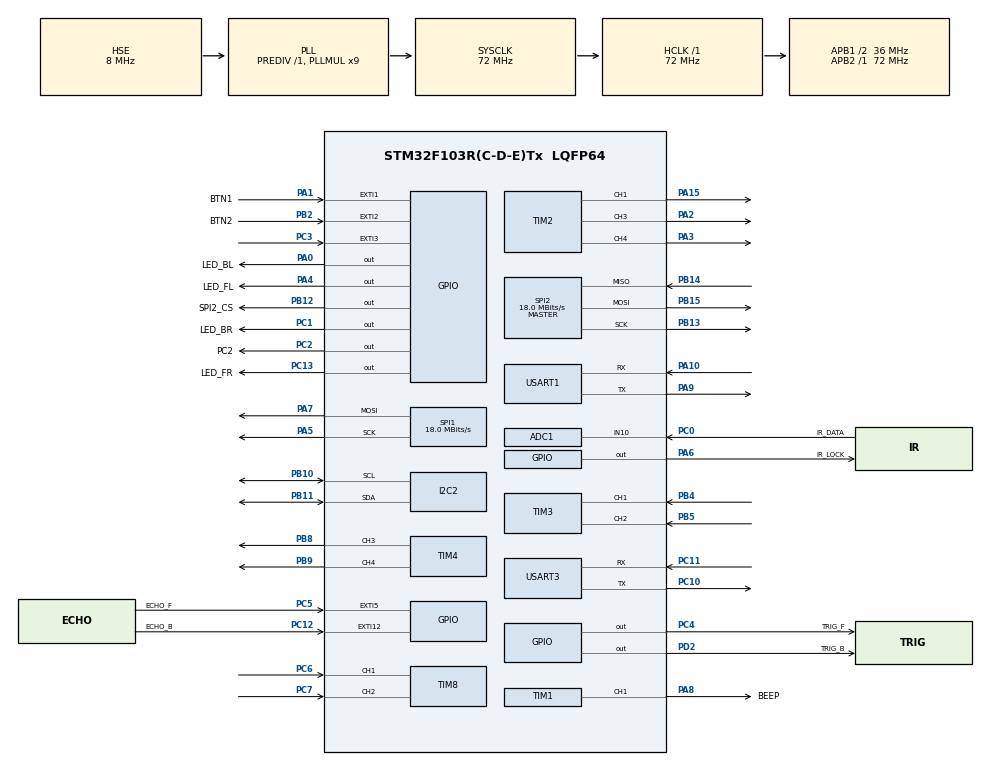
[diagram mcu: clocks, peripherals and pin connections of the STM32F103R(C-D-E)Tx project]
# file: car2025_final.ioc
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ADC1.Channel-9\#ChannelRegularConversion=ADC_CHANNEL_10
ADC1.NbrOfConversionFlag=1
ADC1.Rank-9\#ChannelRegularConversion=1
ADC1.SamplingTime-9\#ChannelRegularConversion=ADC_SAMPLETIME_13CYCLES_5
ADC1.master=1
Dma.ADC1.4.Direction=DMA_PERIPH_TO_MEMORY
Dma.ADC1.4.Instance=DMA1_Channel1
Dma.ADC1.4.MemDataAlignment=DMA_MDATAALIGN_HALFWORD
Dma.ADC1.4.MemInc=DMA_MINC_ENABLE
Dma.ADC1.4.Mode=DMA_NORMAL
Dma.ADC1.4.PeriphDataAlignment=DMA_PDATAALIGN_HALFWORD
Dma.ADC1.4.PeriphInc=DMA_PINC_DISABLE
Dma.ADC1.4.Priority=DMA_PRIORITY_LOW
Dma.Request0=USART1_RX
Dma.Request1=USART1_TX
Dma.Request2=USART3_RX
Dma.Request3=USART3_TX
Dma.Request4=ADC1
Dma.USART1_RX.0.Direction=DMA_PERIPH_TO_MEMORY
Dma.USART1_RX.0.Instance=DMA1_Channel5
Dma.USART1_RX.0.MemDataAlignment=DMA_MDATAALIGN_BYTE
Dma.USART1_RX.0.MemInc=DMA_MINC_ENABLE
Dma.USART1_RX.0.Mode=DMA_NORMAL
Dma.USART1_RX.0.PeriphDataAlignment=DMA_PDATAALIGN_BYTE
Dma.USART1_RX.0.PeriphInc=DMA_PINC_DISABLE
Dma.USART1_RX.0.Priority=DMA_PRIORITY_LOW
Dma.USART1_TX.1.Direction=DMA_MEMORY_TO_PERIPH
Dma.USART1_TX.1.Instance=DMA1_Channel4
Dma.USART1_TX.1.MemDataAlignment=DMA_MDATAALIGN_BYTE
Dma.USART1_TX.1.MemInc=DMA_MINC_ENABLE
Dma.USART1_TX.1.Mode=DMA_NORMAL
Dma.USART1_TX.1.PeriphDataAlignment=DMA_PDATAALIGN_BYTE
Dma.USART1_TX.1.PeriphInc=DMA_PINC_DISABLE
Dma.USART1_TX.1.Priority=DMA_PRIORITY_LOW
Dma.USART3_RX.2.Direction=DMA_PERIPH_TO_MEMORY
Dma.USART3_RX.2.Instance=DMA1_Channel3
Dma.USART3_RX.2.MemDataAlignment=DMA_MDATAALIGN_BYTE
Dma.USART3_RX.2.MemInc=DMA_MINC_ENABLE
Dma.USART3_RX.2.Mode=DMA_NORMAL
Dma.USART3_RX.2.PeriphDataAlignment=DMA_PDATAALIGN_BYTE
Dma.USART3_RX.2.PeriphInc=DMA_PINC_DISABLE
Dma.USART3_RX.2.Priority=DMA_PRIORITY_LOW
Dma.USART3_TX.3.Direction=DMA_MEMORY_TO_PERIPH
Dma.USART3_TX.3.Instance=DMA1_Channel2
Dma.USART3_TX.3.MemDataAlignment=DMA_MDATAALIGN_BYTE
Dma.USART3_TX.3.MemInc=DMA_MINC_ENABLE
Dma.USART3_TX.3.Mode=DMA_NORMAL
Dma.USART3_TX.3.PeriphDataAlignment=DMA_PDATAALIGN_BYTE
Dma.USART3_TX.3.PeriphInc=DMA_PINC_DISABLE
Dma.USART3_TX.3.Priority=DMA_PRIORITY_LOW
I2C2.I2C_Mode=I2C_Standard
Mcu.Family=STM32F1
Mcu.Name=STM32F103R(C-D-E)Tx
Mcu.Package=LQFP64
NVIC.ADC1_2_IRQn=true\:0\:0\:false\:false\:true\:true\:true\:true
NVIC.DMA1_Channel1_IRQn=true\:0\:0\:false\:false\:true\:false\:true\:true
NVIC.DMA1_Channel2_IRQn=true\:0\:0\:false\:false\:true\:false\:true\:true
NVIC.DMA1_Channel3_IRQn=true\:0\:0\:false\:false\:true\:false\:true\:true
NVIC.DMA1_Channel4_IRQn=true\:0\:0\:false\:false\:true\:false\:true\:true
NVIC.DMA1_Channel5_IRQn=true\:0\:0\:false\:false\:true\:false\:true\:true
NVIC.EXTI15_10_IRQn=true\:6\:0\:true\:false\:true\:true\:true\:true
NVIC.EXTI1_IRQn=true\:8\:0\:true\:false\:true\:true\:true\:true
NVIC.EXTI2_IRQn=true\:8\:0\:true\:false\:true\:true\:true\:true
NVIC.EXTI3_IRQn=true\:8\:0\:true\:false\:true\:true\:true\:true
NVIC.EXTI9_5_IRQn=true\:6\:0\:true\:false\:true\:true\:true\:true
NVIC.PriorityGroup=NVIC_PRIORITYGROUP_4
NVIC.TIM5_IRQn=true\:8\:0\:true\:false\:true\:true\:true\:true
NVIC.TIM6_IRQn=true\:5\:0\:true\:false\:true\:true\:true\:true
NVIC.TIM7_IRQn=true\:13\:0\:true\:false\:true\:true\:true\:true
NVIC.USART1_IRQn=true\:14\:0\:true\:false\:true\:true\:true\:true
NVIC.USART3_IRQn=true\:14\:0\:true\:false\:true\:true\:true\:true
PA0-WKUP.GPIO_Label=LED_BL
PA0-WKUP.Signal=GPIO_Output
PA1.GPIO_Label=BTN1
PA1.Signal=GPXTI1
PA10.Mode=Asynchronous
PA10.Signal=USART1_RX
PA13.Mode=Serial_Wire
PA13.Signal=SYS_JTMS-SWDIO
PA14.Mode=Serial_Wire
PA14.Signal=SYS_JTCK-SWCLK
PA15.Signal=S_TIM2_CH1_ETR
PA2.Signal=S_TIM2_CH3
PA3.Signal=S_TIM2_CH4
PA4.GPIO_Label=LED_FL
PA4.Signal=GPIO_Output
PA5.Mode=TX_Only_Simplex_Unidirect_Master
PA5.Signal=SPI1_SCK
PA6.GPIO_Label=IR_LOCK
PA6.Signal=GPIO_Output
PA7.Mode=TX_Only_Simplex_Unidirect_Master
PA7.Signal=SPI1_MOSI
PA8.GPIO_Label=BEEP
PA8.Signal=S_TIM1_CH1
PA9.Mode=Asynchronous
PA9.Signal=USART1_TX
PB10.Mode=I2C
PB10.Signal=I2C2_SCL
PB11.Mode=I2C
PB11.Signal=I2C2_SDA
PB12.GPIO_Label=SPI2_CS
PB12.GPIO_Speed=GPIO_SPEED_FREQ_HIGH
PB12.Signal=GPIO_Output
PB13.Mode=Full_Duplex_Master
PB13.Signal=SPI2_SCK
PB14.Mode=Full_Duplex_Master
PB14.Signal=SPI2_MISO
PB15.Mode=Full_Duplex_Master
PB15.Signal=SPI2_MOSI
PB2.GPIO_Label=BTN2
PB2.Signal=GPXTI2
PB4.Signal=S_TIM3_CH1
PB5.Signal=S_TIM3_CH2
PB8.Signal=S_TIM4_CH3
PB9.Signal=S_TIM4_CH4
PC0.GPIO_Label=IR_DATA
PC0.Signal=ADCx_IN10
PC1.GPIO_Label=LED_BR
PC1.GPIO_Speed=GPIO_SPEED_FREQ_HIGH
PC1.Signal=GPIO_Output
PC10.Mode=Asynchronous
PC10.Signal=USART3_TX
PC11.Mode=Asynchronous
PC11.Signal=USART3_RX
PC12.GPIO_Label=ECHO_B
PC12.GPIO_ModeDefaultEXTI=GPIO_MODE_IT_RISING_FALLING
PC12.Signal=GPXTI12
PC13-TAMPER-RTC.GPIO_Label=LED_FR
PC13-TAMPER-RTC.Signal=GPIO_Output
PC2.GPIO_Label=PC2
PC2.Signal=GPIO_Output
PC3.GPIO_ModeDefaultEXTI=GPIO_MODE_IT_RISING
PC3.Signal=GPXTI3
PC4.GPIO_Label=TRIG_F
PC4.GPIO_Speed=GPIO_SPEED_FREQ_HIGH
PC4.Signal=GPIO_Output
PC5.GPIO_Label=ECHO_F
PC5.GPIO_ModeDefaultEXTI=GPIO_MODE_IT_RISING_FALLING
PC5.Signal=GPXTI5
PC6.Signal=S_TIM8_CH1
PC7.Signal=S_TIM8_CH2
PD0-OSC_IN.Mode=HSE-External-Oscillator
PD0-OSC_IN.Signal=RCC_OSC_IN
PD1-OSC_OUT.Mode=HSE-External-Oscillator
PD1-OSC_OUT.Signal=RCC_OSC_OUT
PD2.GPIO_Label=TRIG_B
PD2.Signal=GPIO_Output
ProjectManager.HeapSize=0x200
ProjectManager.StackSize=0x400
ProjectManager.TargetToolchain=MDK-ARM V5.27
RCC.ADCPresc=RCC_ADCPCLK2_DIV6
RCC.AHBFreq_Value=72000000
RCC.APB1CLKDivider=RCC_HCLK_DIV2
RCC.APB1Freq_Value=36000000
RCC.APB1TimFreq_Value=72000000
RCC.APB2Freq_Value=72000000
RCC.APB2TimFreq_Value=72000000
RCC.HCLKFreq_Value=72000000
RCC.PLLMUL=RCC_PLL_MUL9
RCC.PLLSourceVirtual=RCC_PLLSOURCE_HSE
RCC.SYSCLKFreq_VALUE=72000000
RCC.SYSCLKSource=RCC_SYSCLKSOURCE_PLLCLK
RCC.USBFreq_Value=48000000
RCC.USBPrescaler=RCC_USBCLKSOURCE_PLL_DIV1_5
SH.ADCx_IN10.0=ADC1_IN10,IN10
SH.S_TIM1_CH1.0=TIM1_CH1,PWM Generation1 CH1
SH.S_TIM2_CH1_ETR.0=TIM2_CH1,PWM Generation1 CH1
SH.S_TIM2_CH3.0=TIM2_CH3,PWM Generation3 CH3
SH.S_TIM2_CH4.0=TIM2_CH4,PWM Generation4 CH4
SH.S_TIM3_CH1.0=TIM3_CH1,Encoder_Interface
SH.S_TIM3_CH2.0=TIM3_CH2,Encoder_Interface
SH.S_TIM4_CH3.0=TIM4_CH3,PWM Generation3 CH3
SH.S_TIM4_CH4.0=TIM4_CH4,PWM Generation4 CH4
SH.S_TIM8_CH1.0=TIM8_CH1,Encoder_Interface
SH.S_TIM8_CH2.0=TIM8_CH2,Encoder_Interface
SPI1.BaudRatePrescaler=SPI_BAUDRATEPRESCALER_4
SPI1.CalculateBaudRate=18.0 MBits/s
SPI1.Direction=SPI_DIRECTION_2LINES
SPI1.Mode=SPI_MODE_MASTER
SPI1.VirtualType=VM_MASTER
SPI2.CalculateBaudRate=18.0 MBits/s
SPI2.Direction=SPI_DIRECTION_2LINES
SPI2.Mode=SPI_MODE_MASTER
SPI2.VirtualType=VM_MASTER
TIM1.Channel-PWM\ Generation1\ CH1=TIM_CHANNEL_1
TIM2.Channel-PWM\ Generation1\ CH1=TIM_CHANNEL_1
TIM2.Channel-PWM\ Generation3\ CH3=TIM_CHANNEL_3
TIM2.Channel-PWM\ Generation4\ CH4=TIM_CHANNEL_4
TIM3.EncoderMode=TIM_ENCODERMODE_TI12
TIM4.Channel-PWM\ Generation3\ CH3=TIM_CHANNEL_3
TIM4.Channel-PWM\ Generation4\ CH4=TIM_CHANNEL_4
TIM6.Period=199
TIM6.Prescaler=35999
TIM8.EncoderMode=TIM_ENCODERMODE_TI12
USART1.VirtualMode=VM_ASYNC
USART3.VirtualMode=VM_ASYNC
VP_TIM2_VS_ClockSourceINT.Mode=Internal
VP_TIM4_VS_ClockSourceINT.Mode=Internal
VP_TIM5_VS_ClockSourceINT.Mode=Internal
VP_TIM6_VS_ClockSourceINT.Mode=Enable_Timer
VP_TIM7_VS_ClockSourceINT.Mode=Enable_Timer
board=custom

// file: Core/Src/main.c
/* USER CODE BEGIN Header */
/**
  ******************************************************************************
  * @file           : main.c
  * @brief          : Main program body
  ******************************************************************************
  * @attention
  *
  * Copyright (c) 2024 STMicroelectronics.
  * All rights reserved.
  *
  * This software is licensed under terms that can be found in the LICENSE file
  * in the root directory of this software component.
  * If no LICENSE file comes with this software, it is provided AS-IS.
  *
  ******************************************************************************
  */
/* USER CODE END Header */
#include "main.h"
#include "adc.h"
#include "dma.h"
#include "i2c.h"
#include "spi.h"
#include "tim.h"
#include "usart.h"
#include "gpio.h"
#include "music.h"

/* USER CODE BEGIN Includes */
#include "common.h"
/* USER CODE END Includes */

void SystemClock_Config(void);

int main(void)
{

  /* MCU Configuration--------------------------------------------------------*/

  /* Reset of all peripherals, Initializes the Flash interface and the Systick. */
  HAL_Init();

  /* Configure the system clock */
  SystemClock_Config();

  /* Initialize all configured peripherals */
  MX_GPIO_Init();
  MX_DMA_Init();
  MX_SPI2_Init();
  MX_TIM1_Init();
  MX_USART1_UART_Init();
  MX_USART3_UART_Init();
  MX_TIM6_Init();
  MX_TIM7_Init();
  MX_TIM5_Init();
  MX_I2C2_Init();
  MX_SPI1_Init();
  MX_ADC1_Init();
  MX_TIM2_Init();
  MX_TIM3_Init();
  MX_TIM4_Init();
  MX_TIM8_Init();
	Music_Init();
  /* USER CODE BEGIN 2 */
	System_Init();
  /* USER CODE END 2 */

  /* Infinite loop */
  /* USER CODE BEGIN WHILE */
  while (1)
  {
		UserTasks();

    /* USER CODE END WHILE */

  }
}

void SystemClock_Config(void)
{
  RCC_OscInitTypeDef RCC_OscInitStruct = {0};
  RCC_ClkInitTypeDef RCC_ClkInitStruct = {0};
  RCC_PeriphCLKInitTypeDef PeriphClkInit = {0};

  /** Initializes the RCC Oscillators according to the specified parameters
  * in the RCC_OscInitTypeDef structure.
  */
  RCC_OscInitStruct.OscillatorType = RCC_OSCILLATORTYPE_HSE;
  RCC_OscInitStruct.HSEState = RCC_HSE_ON;
  RCC_OscInitStruct.HSEPredivValue = RCC_HSE_PREDIV_DIV1;
  RCC_OscInitStruct.HSIState = RCC_HSI_ON;
  RCC_OscInitStruct.PLL.PLLState = RCC_PLL_ON;
  RCC_OscInitStruct.PLL.PLLSource = RCC_PLLSOURCE_HSE;
  RCC_OscInitStruct.PLL.PLLMUL = RCC_PLL_MUL9;
  if (HAL_RCC_OscConfig(&RCC_OscInitStruct) != HAL_OK)
  {
    Error_Handler();
  }

  /** Initializes the CPU, AHB and APB buses clocks
  */
  RCC_ClkInitStruct.ClockType = RCC_CLOCKTYPE_HCLK|RCC_CLOCKTYPE_SYSCLK
                              |RCC_CLOCKTYPE_PCLK1|RCC_CLOCKTYPE_PCLK2;
  RCC_ClkInitStruct.SYSCLKSource = RCC_SYSCLKSOURCE_PLLCLK;
  RCC_ClkInitStruct.AHBCLKDivider = RCC_SYSCLK_DIV1;
  RCC_ClkInitStruct.APB1CLKDivider = RCC_HCLK_DIV2;
  RCC_ClkInitStruct.APB2CLKDivider = RCC_HCLK_DIV1;

  if (HAL_RCC_ClockConfig(&RCC_ClkInitStruct, FLASH_LATENCY_2) != HAL_OK)
  {
    Error_Handler();
  }
  PeriphClkInit.PeriphClockSelection = RCC_PERIPHCLK_ADC;
  PeriphClkInit.AdcClockSelection = RCC_ADCPCLK2_DIV6;
  if (HAL_RCCEx_PeriphCLKConfig(&PeriphClkInit) != HAL_OK)
  {
    Error_Handler();
  }
}

void Error_Handler(void)
{
  __disable_irq();
  while (1)
  {
  }
}
